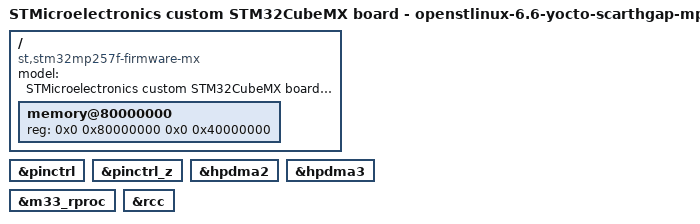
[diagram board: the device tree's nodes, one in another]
// SPDX-License-Identifier: (GPL-2.0-or-later OR BSD-3-Clause)
/*
 * Copyright (C) 2025, STMicroelectronics - All Rights Reserved
 * Author: STM32CubeMX code generation for STMicroelectronics.
 */

/* For more information on Device Tree configuration, please refer to
 * https://wiki.st.com/stm32mpu/wiki/Category:Device_tree_configuration
 */

/dts-v1/;

#include <dt-bindings/pinctrl/stm32-pinfunc.h>
#include <dt-bindings/clock/stm32mp25-clksrc.h>
#include <dt-bindings/soc/stm32mp25-rif.h>
#include <dt-bindings/soc/stm32mp25-risab.h>
#include <dt-bindings/soc/stm32mp25-risaf.h>
#include <dt-bindings/soc/stm32mp25-rifsc.h>
#include "stm32mp257.dtsi"
#include "stm32mp25xf.dtsi"
#include "stm32mp257f-firmware-mx-rcc.dtsi"
#include "stm32mp257f-firmware-mx-resmem.dtsi"
#include "stm32mp257f-firmware-mx-rif.dtsi"
#include "stm32mp25xxak-pinctrl.dtsi"

/* USER CODE BEGIN includes */
/* USER CODE END includes */

/ {
	model = "STMicroelectronics custom STM32CubeMX board - openstlinux-6.6-yocto-scarthgap-mpu-v24.11.06";
	compatible = "st,stm32mp257f-firmware-mx", "st,stm32mp257";

	memory@80000000 {
		device_type = "memory";
		reg = <0x0 0x80000000 0x0 0x40000000>;

		/* USER CODE BEGIN memory */
		/* USER CODE END memory */
	};

	/* USER CODE BEGIN root */
	/* USER CODE END root */

}; /*root*/

&pinctrl {
	/* USER CODE BEGIN pinctrl */
	/* USER CODE END pinctrl */
};

&pinctrl_z {
	/* USER CODE BEGIN pinctrl_z */
	/* USER CODE END pinctrl_z */
};

&hpdma2 {
	status = "okay";

	/* USER CODE BEGIN hpdma2 */
	/* USER CODE END hpdma2 */
};

&hpdma3 {
	status = "okay";

	/* USER CODE BEGIN hpdma3 */
	/* USER CODE END hpdma3 */
};

&m33_rproc {
	status = "okay";

	/* USER CODE BEGIN m33_rproc */
	/* USER CODE END m33_rproc */
};

&rcc {
	status = "okay";

	/* USER CODE BEGIN rcc */
	/* USER CODE END rcc */
};

/* USER CODE BEGIN addons */
/* USER CODE END addons */

